# PIC18LF6621 register map
Vendor: Microchip
Architecture 18xxxx. Special function registers and configuration words.
Registers are 8-bit, read-write, reset 0x0 unless marked. A register's access mark holds for its fields unless they carry their own. Addresses are absolute, and some are shared; only a register's first bit layout is shown; lines under a group give offsets from that group; [hi:lo] are bit positions; {n}, {i} and the like mark numbered series; 'fields as' and 'values as' point back to an identical list; <NAME> marks a mode.

## Further device data
pins=1: RE1/WR/P2C; 2: RE0/RD/P2D; 3: RG0/ECCP3/P3A; 4: RG1/TX2/CK2; 5: RG2/RX2/DT2; 6: RG3/CCP4/P3D; 7: MCLR/Vpp/RG5; 8: RG4/CCP5/P1D; 9: Vss; 10: Vdd; 11: RF7/SS; 12: RF6/AN11; 13: RF5/AN10/CVref; 14: RF4/AN9; 15: RF3/AN8; 16: RF2/AN7/C1OUT; 17: RF1/AN6/C2OUT; 18: RF0/AN5; 19: Avdd; 20: Avss; 21: RA3/AN3/Vref+; 22: RA2/AN2/Vref-; 23: RA1/AN1; 24: RA0/AN0; 25: Vss; 26: Vdd; 27: RA5/AN4/LVDIN; 28: RA4/T0CKI; 29: RC1/T1OSI/ECCP2/P2A; 30: RC0/T1OSO/T13CKI; 31: RC6/TX1/CK1; 32: RC7/RX1/DT1; 33: RC2/ECCP1/P1A; 34: RC3/SCK/SCL; 35: RC4/SDI/SDA; 36: RC5/SDO; 37: RB7/KBI3/PGD; 38: Vdd; 39: OSC1/CLKI; 40: OSC2/CLKO/RA6; 41: Vss; 42: RB6/KBI2/PGC; 43: RB5/KBI1/PGM; 44: RB4/KBI0; 45: RB3/INT3; 46: RB2/INT2; 47: RB1/INT1; 48: RB0/INT0/FLT0; 49: RD7/PSP7; 50: RD6/PSP6; 51: RD5/PSP5; 52: RD4/PSP4; 53: RD3/PSP3; 54: RD2/PSP2; 55: RD1/PSP1; 56: Vss; 57: Vdd; 58: RD0/PSP0; 59: RE7/ECCP2/P2A; 60: RE6/P1B; 61: RE5/P1C; 62: RE4/P3B; 63: RE3/P3C; 64: RE2/CS/P2B

## CONFIG — Configuration words, addresses in ProgramSpace
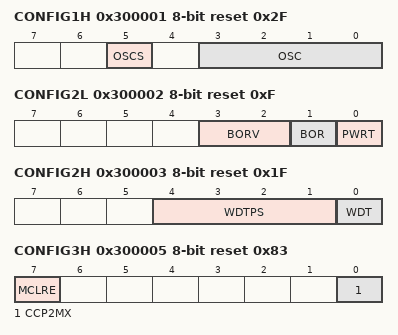
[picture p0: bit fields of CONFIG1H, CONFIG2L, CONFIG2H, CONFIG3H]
0x300001 CONFIG1H reset 0x2F
  [5] OSCS — Oscillator System Clock Switch Enable bit
    0=ON (Timer1 oscillator system clock switch option is enabled (oscillator switching is enabled)); 1=OFF (Oscillator system clock switch option is disabled (main oscillator is source))
  [3:0] OSC — Oscillator Selection bits
    15=RC-OSC2 as RA6; 14=HSSWPLL (HS oscillator with SW enabled 4x PLL); 13=ECIOSWPLL (EC oscillator with OSC2 configured as RA6 and SW enabled 4x PLL); 12=ECIOPLL (EC oscillator with OSC2 configured as RA6 and HW enabled 4x PLL); 7=RCIO (RC oscillator with OSC2 configured as RA6); 6=HSPLL (HS oscillator with HW enabled 4x PLL); 5=ECIO (EC oscillator with OSC2 configured as RA6); 4=EC (EC oscillator with OSC2 configured as divide by 4 clock output); 3=RC (RC oscillator with OSC2 configured as divide by 4 clock output); 2=HS (HS oscillator); 1=XT (XT oscillator); 0=LP (LP oscillator)
0x300002 CONFIG2L reset 0xF
  [3:2] BORV — Brown-out Reset Voltage bits
    3=VBOR set to 2.0V; 2=VBOR set to 2.7V; 1=VBOR set to 4.2V; 0=VBOR set to 4.5V
  [1] BOR — Brown-out Reset Enable bit
    1=ON (Brown-out Reset enabled); 0=OFF (Brown-out Reset disabled)
  [0] PWRT — Power-up Timer Enable bit
    1=OFF (PWRT disabled); 0=ON (PWRT enabled)
0x300003 CONFIG2H reset 0x1F
  [4:1] WDTPS — Watchdog Timer Postscaler Select bits
    15=1:32768; 14=1:16384; 13=1:8192; 12=1:4096; 11=1:2048; 10=1:1024; 9=1:512; 8=1:256; 7=1:128; 6=1:64; 5=1:32; 4=1:16; 3=1:8; 2=1:4; 1=1:2; 0=1:1
  [0] WDT — Watchdog Timer Enable bit
    1=ON (WDT enabled); 0=OFF (WDT disabled (control is placed on the SWDTEN bit))
0x300004 CONFIG3L reset 0x83
0x300005 CONFIG3H reset 0x83
  [7] MCLRE — MCLR Enable bit
    1=ON (MCLR pin enabled, RG5 input pin disabled); 0=OFF (RG5 input enabled, MCLR disabled)
  [0] CCP2MX — ECCP2 Mux bit
    1=PORTC (Multiplexed with RC1); 0=PORTBE (Multiplexed with RB3 or RE7)
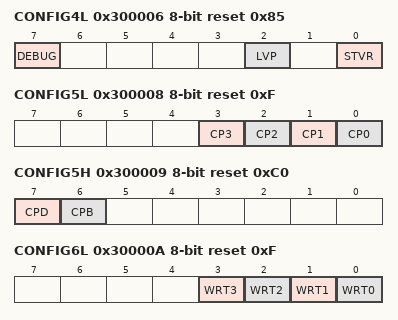
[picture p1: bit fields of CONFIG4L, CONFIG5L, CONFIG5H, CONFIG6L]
0x300006 CONFIG4L reset 0x85
  [7] DEBUG — Background Debugger Enable bit
    1=OFF (Background debugger disabled. RB6 and RB7 configured as general purpose I/O pins.); 0=ON (Background debugger enabled. RB6 and RB7 are dedicated to in-circuit debug.)
  [2] LVP — Low-Voltage ICSP Enable bit
    1=ON (Low-Voltage ICSP enabled); 0=OFF (Low-Voltage ICSP disabled)
  [0] STVR — Stack Full/Underflow Reset Enable bit
    1=ON (Stack full/underflow will cause Reset); 0=OFF (Stack full/underflow will not cause Reset)
0x300008 CONFIG5L reset 0xF
  [3] CP3 — Code Protection bit
    1=OFF (Block 3 (00C000-00FFFFh) not code-protected); 0=ON (Block 3 (00C000-00FFFFh) code-protected)
  [2] CP2 — Code Protection bit
    1=OFF (Block 2 (008000-00BFFFh) not code-protected); 0=ON (Block 2 (008000-00BFFFh) code-protected)
  [1] CP1 — Code Protection bit
    1=OFF (Block 1 (004000-007FFFh) not code-protected); 0=ON (Block 1 (004000-007FFFh) code-protected)
  [0] CP0 — Code Protection bit
    1=OFF (Block 0 (000800-003FFFh) not code-protected); 0=ON (Block 0 (000800-003FFFh) code-protected)
0x300009 CONFIG5H reset 0xC0
  [7] CPD — Data EEPROM Code Protection bit
    1=OFF (Data EEPROM not code-protected); 0=ON (Data EEPROM code-protected)
  [6] CPB — Boot Block Code Protection bit
    1=OFF (Boot block (000000-0007FFh) not code-protected); 0=ON (Boot block (000000-0007FFh) code-protected)
0x30000A CONFIG6L reset 0xF
  [3] WRT3 — Write Protection bit
    1=OFF (Block 3 (00C000-00FFFFh) not write-protected); 0=ON (Block 3 (00C000-00FFFFh) write-protected)
  [2] WRT2 — Write Protection bit
    1=OFF (Block 2 (008000-00BFFFh) not write-protected); 0=ON (Block 2 (008000-00BFFFh) write-protected)
  [1] WRT1 — Write Protection bit
    1=OFF (Block 1 (004000-007FFFh) not write-protected); 0=ON (Block 1 (004000-007FFFh) write-protected)
  [0] WRT0 — Write Protection bit
    1=OFF (Block 0 (000800-003FFFh) not write-protected); 0=ON (Block 0 (000800-003FFFh) write-protected)
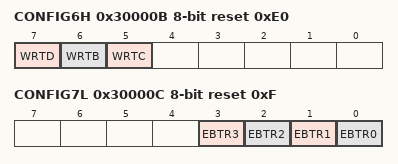
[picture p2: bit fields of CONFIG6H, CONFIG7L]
0x30000B CONFIG6H reset 0xE0
  [7] WRTD — Data EEPROM Write Protection bit
    1=OFF (Data EEPROM not write-protected); 0=ON (Data EEPROM write-protected)
  [6] WRTB — Boot Block Write Protection bit
    1=OFF (Boot block (000000-0007FFh) not write-protected); 0=ON (Boot block (000000-0007FFh) write-protected)
  [5] WRTC — Configuration Register Write Protection bit
    1=OFF (Configuration registers (300000-3000FFh) not write-protected); 0=ON (Configuration registers (300000-3000FFh) write-protected)
0x30000C CONFIG7L reset 0xF
  [3] EBTR3 — Table Read Protection bit
    1=OFF (Block 3 (00C000-00FFFFh) not protected from table reads executed in other blocks); 0=ON (Block 3 (00C000-00FFFFh) protected from table reads executed in other blocks)
  [2] EBTR2 — Table Read Protection bit
    1=OFF (Block 2 (008000-00BFFFh) not protected from table reads executed in other blocks); 0=ON (Block 2 (008000-00BFFFh) protected from table reads executed in other blocks)
  [1] EBTR1 — Table Read Protection bit
    1=OFF (Block 1 (004000-007FFFh) not protected from table reads executed in other blocks); 0=ON (Block 1 (004000-007FFFh) protected from table reads executed in other blocks)
  [0] EBTR0 — Table Read Protection bit
    1=OFF (Block 0 (000800-003FFFh) not protected from table reads executed in other blocks); 0=ON (Block 0 (000800-003FFFh) protected from table reads executed in other blocks)
0x30000D CONFIG7H reset 0x40
  [6] EBTRB — Boot Block Table Read Protection bit
    1=OFF (Boot block (000000-0007FFh) not protected from table reads executed in other blocks); 0=ON (Boot block (000000-0007FFh) protected from table reads executed in other blocks)
